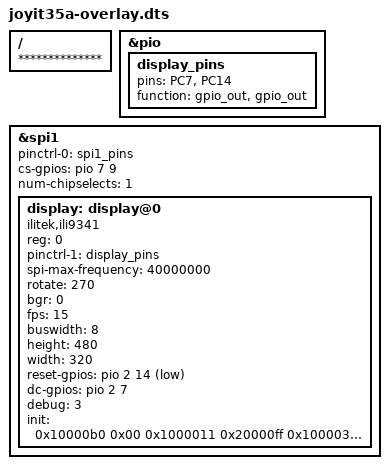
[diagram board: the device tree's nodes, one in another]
/*
OrangePi Zero 3 -> ILI9486 LCD connections
SPI CLOCK = PH6
SPI DO (LCD MISO) = PH8 (OPIZ MISO)
SPI DI (LCD MOSI) = PH7 (OPIZ MOSI)
LCD DATA/CONTROL = PC7 *
LCD RESET = PC14 * could be any GPIO pin I want
CHIP SELECT = PH9
VCC = 3.3V PIN 17
GND = GND PIN 20
*/

/dts-v1/;
/plugin/;
/{
    compatible = "**************"; /*what is the H618*/
	fragment@0 {
	    target = <&pio>;
	    __overlay__{
	        display_pins: display_pins {
                    pins = "PC7", "PC14"; /* reset, DC pins, order does not matter*/
                    function = "gpio_out", "gpio_out";
                };
            };
	};
	fragment@1 {
        target = <&spi1>;
        __overlay__ {
            /* needed to avoid dtc warning */
            #address-cells = <1>;
            #size-cells = <0>;
            status="okay";
            pinctrl-names = "default";
            pinctrl-0 = <&spi1_pins>; /* Mux the PI to make sure they are set in spi Mode */
            cs-gpios = <&pio 7 9 0>;  /* PH9 chip select, H=7 */
            num-chipselects = <1>;
            display: display@0 {
                /*compatible = "adafruit,yx320qv29","ilitek,ili9486";*/
                compatible = "ilitek,ili9341";
                reg = <0>;
                pinctrl-names = "default";
                pinctrl-1 = <&display_pins>;
                spi-max-frequency = <40000000>;
                rotate = <270>; /* rotate for ili9486, rotation for yx320qv29 */
                bgr=<0>;
                fps = <15>;
                buswidth = <8>;
                height = <480>;
                width = <320>;
                reset-gpios = <&pio 2 14 1>; /* PC14 reset pin*/
                dc-gpios = <&pio 2 7 0>; /* PC7 Data control pin */
                debug = <3>;
                init = <0x10000b0 0x00
                        0x1000011
			0x20000ff
			0x100003a 0x55
			0x1000036 0x28
			0x10000c2 0x44
			0x10000c5 0x00 0x00 0x00 0x00
			0x10000e0 0x0f 0x1f 0x1c 0x0c 0x0f 0x08 0x48 0x98 0x37 0x0a 0x13 0x04 0x11 0x0d 0x00
			0x10000e1 0x0f 0x32 0x2e 0x0b 0x0d 0x05 0x47 0x75 0x37 0x06 0x10 0x03 0x24 0x20 0x00
			0x10000e2 0x0f 0x32 0x2e 0x0b 0x0d 0x05 0x47 0x75 0x37 0x06 0x10 0x03 0x24 0x20 0x00
			0x1000036 0x28
			0x1000011
			0x1000029>;
            };
        };
    };


    __overrides__ {
        rotate =  <&display>,"rotate:0";
        fps =     <&display>,"fps:0";
        debug =   <&display>,"debug:0";
    };
};
 
 
